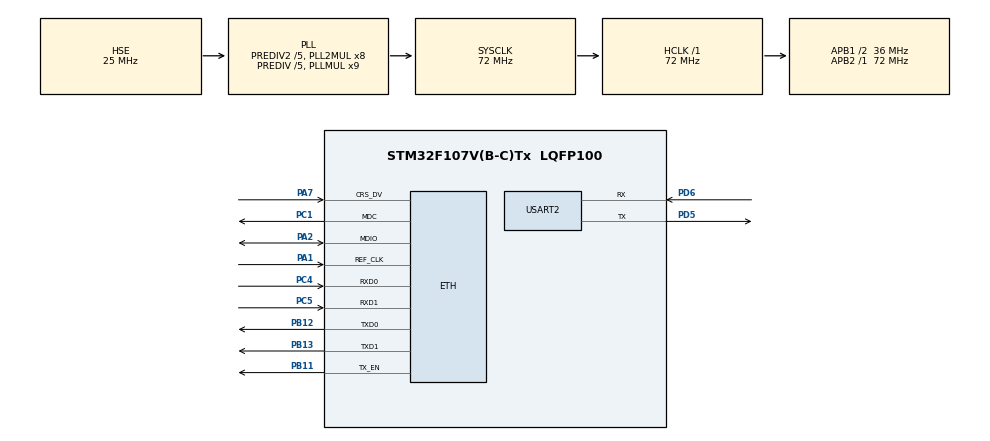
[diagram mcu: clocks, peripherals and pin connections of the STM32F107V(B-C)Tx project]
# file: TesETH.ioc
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ETH.MediaInterface=ETH_MEDIA_INTERFACE_RMII
ETH.PHY_Name_RMII=LAN8742A_PHY_ADDRESS
LWIP.API_LIB_DEBUG=LWIP_DBG_ON
LWIP.API_MSG_DEBUG=LWIP_DBG_ON
LWIP.DHCP_DEBUG=LWIP_DBG_ON
LWIP.ETHARP_DEBUG=LWIP_DBG_ON
LWIP.ICMP_DEBUG=LWIP_DBG_ON
LWIP.INET_DEBUG=LWIP_DBG_ON
LWIP.IP_DEBUG=LWIP_DBG_ON
LWIP.LWIP_DBG_MIN_LEVEL=LWIP_DBG_LEVEL_ALL
LWIP.LWIP_DBG_TYPES_ON=LWIP_DBG_ON
LWIP.LWIP_IPV6=0
LWIP.NETIF_DEBUG=LWIP_DBG_ON
LWIP.PBUF_DEBUG=LWIP_DBG_ON
LWIP.RAW_DEBUG=LWIP_DBG_ON
LWIP.SYS_DEBUG=LWIP_DBG_ON
LWIP.TCPIP_DEBUG=LWIP_DBG_ON
LWIP.TCP_DEBUG=LWIP_DBG_ON
LWIP.TCP_INPUT_DEBUG=LWIP_DBG_ON
LWIP.TCP_OUTPUT_DEBUG=LWIP_DBG_ON
LWIP.Version=v2.0.3_Cube
Mcu.Family=STM32F1
Mcu.Name=STM32F107V(B-C)Tx
Mcu.Package=LQFP100
NVIC.PriorityGroup=NVIC_PRIORITYGROUP_4
OSC_IN.Mode=HSE-External-Oscillator
OSC_IN.Signal=RCC_OSC_IN
OSC_OUT.Mode=HSE-External-Oscillator
OSC_OUT.Signal=RCC_OSC_OUT
PA1.Mode=RMII
PA1.Signal=ETH_REF_CLK
PA2.Mode=RMII
PA2.Signal=ETH_MDIO
PA7.Mode=RMII
PA7.Signal=ETH_CRS_DV
PB11.Mode=RMII
PB11.Signal=ETH_TX_EN
PB12.Mode=RMII
PB12.Signal=ETH_TXD0
PB13.Mode=RMII
PB13.Signal=ETH_TXD1
PC1.Mode=RMII
PC1.Signal=ETH_MDC
PC4.Mode=RMII
PC4.Signal=ETH_RXD0
PC5.Mode=RMII
PC5.Signal=ETH_RXD1
PD5.Mode=Asynchronous
PD5.Signal=USART2_TX
PD6.Mode=Asynchronous
PD6.Signal=USART2_RX
ProjectManager.HeapSize=0x200
ProjectManager.StackSize=0x400
ProjectManager.TargetToolchain=TrueSTUDIO
RCC.AHBFreq_Value=72000000
RCC.APB1CLKDivider=RCC_HCLK_DIV2
RCC.APB1Freq_Value=36000000
RCC.APB1TimFreq_Value=72000000
RCC.APB2Freq_Value=72000000
RCC.APB2TimFreq_Value=72000000
RCC.HCLKFreq_Value=72000000
RCC.HSEDivPLL=RCC_HSE_PREDIV_DIV5
RCC.HSE_VALUE=25000000
RCC.PLLMUL=RCC_PLL_MUL9
RCC.PLLSourceVirtual=RCC_PLLSOURCE_HSE
RCC.Prediv1Source=RCC_PREDIV1_SOURCE_PLL2
RCC.Prediv2=RCC_HSE_PREDIV2_DIV5
RCC.SYSCLKFreq_VALUE=72000000
RCC.SYSCLKSource=RCC_SYSCLKSOURCE_PLLCLK
RCC.USBFreq_Value=48000000
USART2.VirtualMode=VM_ASYNC
VP_LWIP_VS_Enabled.Mode=Enabled
VP_SYS_VS_ND.Mode=No_Debug
board=custom

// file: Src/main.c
/* USER CODE BEGIN Header */
/**
  ******************************************************************************
  * @file           : main.c
  * @brief          : Main program body
  ******************************************************************************
  * @attention
  *
  * <h2><center>&copy; Copyright (c) 2020 STMicroelectronics.
  * All rights reserved.</center></h2>
  *
  * This software component is licensed by ST under Ultimate Liberty license
  * SLA0044, the "License"; You may not use this file except in compliance with
  * the License. You may obtain a copy of the License at:
  *                             www.st.com/SLA0044
  *
  ******************************************************************************
  */
/* USER CODE END Header */

#include "main.h"
#include "lwip.h"

UART_HandleTypeDef huart2;

void SystemClock_Config(void);
static void MX_GPIO_Init(void);
static void MX_USART2_UART_Init(void);

/* USER CODE BEGIN 0 */
void vprint_o(const char *fmt, va_list argp)
{
    char string[200];
    if(0 < vsprintf(string,fmt,argp)) // build string
    {
        HAL_UART_Transmit(&huart2, (uint8_t*)string, strlen(string), 0xffffff); // send message via UART
    }
}

void my_printf(const char *fmt, ...) // custom printf() function
{
    va_list argp;
    va_start(argp, fmt);
    vprint_o(fmt, argp);
    va_end(argp);
}
/* USER CODE END 0 */

int main(void)
{

  /* MCU Configuration--------------------------------------------------------*/

  /* Reset of all peripherals, Initializes the Flash interface and the Systick. */
  HAL_Init();

  /* Configure the system clock */
  SystemClock_Config();

  /* Initialize all configured peripherals */
  MX_GPIO_Init();
  MX_LWIP_Init();
  MX_USART2_UART_Init();
  /* USER CODE BEGIN 2 */
  my_printf("Deine Oma faehrt im Huehnerstall Motorrad\n");
  LWIP_PLATFORM_DIAG(("Debug Test %d\n", 1));
  LWIP_PLATFORM_DIAG(("Debug Test %d\n", 2));
  /* USER CODE END 2 */

  /* Infinite loop */
  while (1)
  {

    /* USER CODE BEGIN 3 */
	  MX_LWIP_Process();
  }
  /* USER CODE END 3 */
}

void SystemClock_Config(void)
{
  RCC_OscInitTypeDef RCC_OscInitStruct = {0};
  RCC_ClkInitTypeDef RCC_ClkInitStruct = {0};

  /** Initializes the CPU, AHB and APB busses clocks
  */
  RCC_OscInitStruct.OscillatorType = RCC_OSCILLATORTYPE_HSE;
  RCC_OscInitStruct.HSEState = RCC_HSE_ON;
  RCC_OscInitStruct.HSEPredivValue = RCC_HSE_PREDIV_DIV5;
  RCC_OscInitStruct.HSIState = RCC_HSI_ON;
  RCC_OscInitStruct.Prediv1Source = RCC_PREDIV1_SOURCE_PLL2;
  RCC_OscInitStruct.PLL.PLLState = RCC_PLL_ON;
  RCC_OscInitStruct.PLL.PLLSource = RCC_PLLSOURCE_HSE;
  RCC_OscInitStruct.PLL.PLLMUL = RCC_PLL_MUL9;
  RCC_OscInitStruct.PLL2.PLL2State = RCC_PLL2_ON;
  RCC_OscInitStruct.PLL2.PLL2MUL = RCC_PLL2_MUL8;
  RCC_OscInitStruct.PLL2.HSEPrediv2Value = RCC_HSE_PREDIV2_DIV5;
  if (HAL_RCC_OscConfig(&RCC_OscInitStruct) != HAL_OK)
  {
    Error_Handler();
  }
  /** Initializes the CPU, AHB and APB busses clocks
  */
  RCC_ClkInitStruct.ClockType = RCC_CLOCKTYPE_HCLK|RCC_CLOCKTYPE_SYSCLK
                              |RCC_CLOCKTYPE_PCLK1|RCC_CLOCKTYPE_PCLK2;
  RCC_ClkInitStruct.SYSCLKSource = RCC_SYSCLKSOURCE_PLLCLK;
  RCC_ClkInitStruct.AHBCLKDivider = RCC_SYSCLK_DIV1;
  RCC_ClkInitStruct.APB1CLKDivider = RCC_HCLK_DIV2;
  RCC_ClkInitStruct.APB2CLKDivider = RCC_HCLK_DIV1;

  if (HAL_RCC_ClockConfig(&RCC_ClkInitStruct, FLASH_LATENCY_2) != HAL_OK)
  {
    Error_Handler();
  }
  /** Configure the Systick interrupt time
  */
  __HAL_RCC_PLLI2S_ENABLE();
}

static void MX_USART2_UART_Init(void)
{

  huart2.Instance = USART2;
  huart2.Init.BaudRate = 115200;
  huart2.Init.WordLength = UART_WORDLENGTH_8B;
  huart2.Init.StopBits = UART_STOPBITS_1;
  huart2.Init.Parity = UART_PARITY_NONE;
  huart2.Init.Mode = UART_MODE_TX_RX;
  huart2.Init.HwFlowCtl = UART_HWCONTROL_NONE;
  huart2.Init.OverSampling = UART_OVERSAMPLING_16;
  if (HAL_UART_Init(&huart2) != HAL_OK)
  {
    Error_Handler();
  }

}

static void MX_GPIO_Init(void)
{

  /* GPIO Ports Clock Enable */
  __HAL_RCC_GPIOC_CLK_ENABLE();
  __HAL_RCC_GPIOA_CLK_ENABLE();
  __HAL_RCC_GPIOB_CLK_ENABLE();
  __HAL_RCC_GPIOD_CLK_ENABLE();

}

void Error_Handler(void)
{
}

/************************ (C) COPYRIGHT STMicroelectronics *****END OF FILE****/
